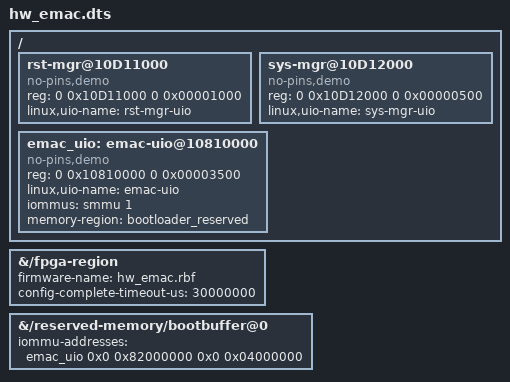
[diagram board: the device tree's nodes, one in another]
/*
 * SPDX-FileCopyrightText: Copyright (C) 2024 Intel Corporation
 * SPDX-FileCopyrightText: Copyright (C) 2025 Altera Corporation
 * SPDX-License-Identifier: MIT-0
 */

/dts-v1/;
/plugin/;
/ {
	fragment@0 {
		target-path = "/fpga-region";
		__overlay__ {
			firmware-name = "hw_emac.rbf";
			config-complete-timeout-us = <30000000>;
		};
	};
	fragment@1 {
		target-path = "/";
		__overlay__ {
			#address-cells = <0x2>;
			#size-cells = <0x2>;

			rst-mgr@10D11000 {
				compatible = "no-pins,demo";
				reg = <0 0x10D11000 0 0x00001000>;
				reg-names = "rst-mgr";
				linux,uio-name = "rst-mgr-uio";
			};

			sys-mgr@10D12000 {
				compatible = "no-pins,demo";
				reg = <0 0x10D12000 0 0x00000500>;
				reg-names = "sys-mgr";
				linux,uio-name = "sys-mgr-uio";
			};

			emac_uio: emac-uio@10810000 {
				compatible = "no-pins,demo";
				reg = <0 0x10810000 0 0x00003500>;
				reg-names = "emac-uio";
				linux,uio-name = "emac-uio";
				iommus = <&smmu 1>;
				memory-region = <&bootloader_reserved>;
			};
		};
	};
	fragment@2 {
		target-path = "/reserved-memory/bootbuffer@0";
		__overlay__ {
			iommu-addresses = <&emac_uio 0x0 0x82000000 0x0 0x04000000>;
		};
	};
};

